# PIC16LF1709 register map
Vendor: Microchip
Registers are 8-bit, read-write, reset 0x0 unless marked. A register's access mark holds for its fields unless they carry their own. Addresses are absolute, and some are shared; only a register's first bit layout is shown; [hi:lo] are bit positions; {n}, {i} and the like mark numbered series.

## CONFIG — Configuration words, addresses in ProgramSpace
0x8007 CONFIG1 14-bit reset 0x3FFF
  [13] FCMEN — Fail-Safe Clock Monitor Enable
    1=ON (Fail-Safe Clock Monitor is enabled); 0=OFF (Fail-Safe Clock Monitor is disabled)
  [12] IESO — Internal/External Switchover Mode
    1=ON (Internal/External Switchover Mode is enabled); 0=OFF (Internal/External Switchover Mode is disabled)
  [11] CLKOUTEN — Clock Out Enable
    1=OFF (CLKOUT function is disabled. I/O or oscillator function on the CLKOUT pin); 0=ON (CLKOUT function is enabled on the CLKOUT pin)
  [10:9] BOREN — Brown-out Reset Enable
    3=ON (Brown-out Reset enabled); 2=NSLEEP (Brown-out Reset enabled while running and disabled in Sleep); 1=SBODEN (Brown-out Reset controlled by the SBOREN bit in the BORCON register); 0=OFF (Brown-out Reset disabled)
  [7] CP — Flash Program Memory Code Protection
    1=OFF (Program memory code protection is disabled); 0=ON (Program memory code protection is enabled)
  [6] MCLRE — MCLR Pin Function Select
    1=ON (MCLR/VPP pin function is MCLR); 0=OFF (MCLR/VPP pin function is digital input)
  [5] PWRTE — Power-up Timer Enable
    1=OFF (PWRT disabled); 0=ON (PWRT enabled)
  [4:3] WDTE — Watchdog Timer Enable
    3=ON (WDT enabled); 2=NSLEEP (WDT enabled while running and disabled in Sleep); 1=SWDTEN (WDT controlled by the SWDTEN bit in the WDTCON register); 0=OFF (WDT disabled)
  [2:0] FOSC — Oscillator Selection Bits
    7=ECH (ECH, External Clock, High Power Mode (4-20 MHz): device clock supplied to CLKIN pins); 6=ECM (ECM, External Clock, Medium Power Mode (0.5-4 MHz): device clock supplied to CLKIN pins); 5=ECL (ECL, External Clock, Low Power Mode (0-0.5 MHz): device clock supplied to CLKIN pins); 4=INTOSC (INTOSC oscillator: I/O function on CLKIN pin); 3=EXTRC (EXTRC oscillator: External RC circuit connected to CLKIN pin); 2=HS (HS Oscillator, High-speed crystal/resonator connected between OSC1 and OSC2 pins); 1=XT (XT Oscillator, Crystal/resonator connected between OSC1 and OSC2 pins); 0=LP (LP Oscillator, Low-power crystal connected between OSC1 and OSC2 pins)
0x8008 CONFIG2 14-bit reset 0x3FFF
  [13] LVP — Low-Voltage Programming Enable
    1=ON (Low-voltage programming enabled); 0=OFF (High-voltage on MCLR/VPP must be used for programming)
  [12] DEBUG — In-Circuit Debugger Mode
    1=OFF (In-Circuit Debugger disabled, ICSPCLK and ICSPDAT are general purpose I/O pins); 0=ON (In-Circuit Debugger enabled, ICSPCLK and ICSPDAT are dedicated to the debugger)
  [11] LPBOR — Low-Power Brown Out Reset
    1=OFF (Low-Power BOR is disabled); 0=ON (Low-Power BOR is enabled)
  [10] BORV — Brown-out Reset Voltage Selection
    1=LO (Brown-out Reset Voltage (Vbor), low trip point selected.); 0=HI (Brown-out Reset Voltage (Vbor), high trip point selected.)
  [9] STVREN — Stack Overflow/Underflow Reset Enable
    1=ON (Stack Overflow or Underflow will cause a Reset); 0=OFF (Stack Overflow or Underflow will not cause a Reset)
  [8] PLLEN — Phase Lock Loop enable
    1=ON (4x PLL is enabled); 0=OFF (4x PLL is disabled)
  [7] ZCDDIS — Zero-cross detect disable
    1=ON (ZCD disabled. ZCD can be enabled by setting the ZCDSEN bit of ZCDCON); 0=OFF (ZCD always enabled)
  [2] PPS1WAY — Peripheral Pin Select one-way control
    1=ON (The PPSLOCK bit cannot be cleared once it is set by software); 0=OFF (The PPSLOCK bit can be set and cleared repeatedly by software)
  [1:0] WRT — Flash Memory Self-Write Protection
    3=OFF (Write protection off); 2=BOOT (000h to 1FFh write protected, 200h to 1FFFh may be modified by EECON control); 1=HALF (000h to FFFh write protected, 1000h to 1FFFh may be modified by EECON control); 0=ALL (000h to 1FFFh write protected, no addresses may be modified by EECON control)

## CLC
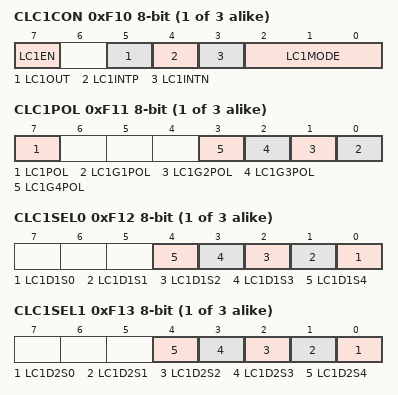
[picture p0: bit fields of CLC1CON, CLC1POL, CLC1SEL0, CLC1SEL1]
{0xF06+0xA*i} CLC{i}CON (i=1..3) — Configurable logic cell control
  [7] LC{i}EN, [5] LC{i}OUT ro, [4] LC{i}INTP, [3] LC{i}INTN, [2:0] LC{i}MODE
{0xF07+0xA*i} CLC{i}POL reset not defined (i=1..3) — Polarity control (power-on value 0---xxxx)
  [7] LC{i}POL, [n-1] LC{i}G{n}POL (n=1..4)
{0xF08+0xA*i} CLC{i}SEL0 reset not defined (i=1..3) — Input select register 1 (power-on value ---xxxxx)
  [n] LC{i}D1S{n} (n=0..4)
{0xF09+0xA*i} CLC{i}SEL1 reset not defined (i=1..3) — Input select register 1 (power-on value ---xxxxx)
  [n] LC{i}D2S{n} (n=0..4)
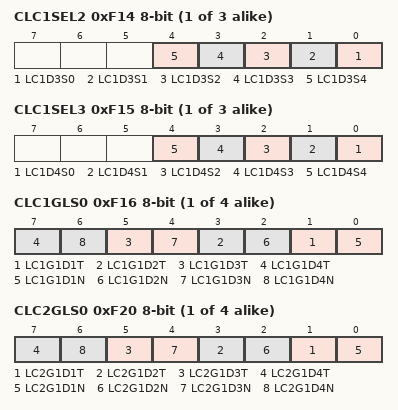
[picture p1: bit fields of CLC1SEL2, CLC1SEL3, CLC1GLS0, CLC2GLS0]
{0xF0A+0xA*i} CLC{i}SEL2 reset not defined (i=1..3) — Input select register 2 (power-on value ---xxxxx)
  [n] LC{i}D3S{n} (n=0..4)
{0xF0B+0xA*i} CLC{i}SEL3 reset not defined (i=1..3) — Input select register 3 (power-on value ---xxxxx)
  [n] LC{i}D4S{n} (n=0..4)
{0xF16+i} CLC1GLS{i} reset not defined (i=0..3) — Gate logic select register {i} (power-on value xxxxxxxx)
  [2n-1] LC1G{i+1}D{n}T (n=1..4), [2n-2] LC1G{i+1}D{n}N (n=1..4)
{0xF20+i} CLC2GLS{i} reset not defined (i=0..3) — Gate logic select register {i} (power-on value xxxxxxxx)
  [2n-1] LC2G{i+1}D{n}T (n=1..4), [2n-2] LC2G{i+1}D{n}N (n=1..4)
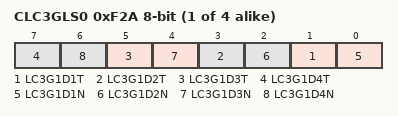
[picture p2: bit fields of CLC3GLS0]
{0xF2A+i} CLC3GLS{i} reset not defined (i=0..3) — Gate logic select register {i} (power-on value xxxxxxxx)
  [2n-1] LC3G{i+1}D{n}T (n=1..4), [2n-2] LC3G{i+1}D{n}N (n=1..4)
